AUTOSAR XML (schema 00044)
package /ComponentTypes
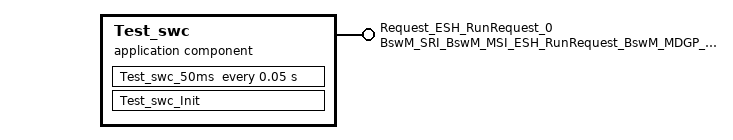
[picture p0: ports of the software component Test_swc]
  application sw component type Test_swc
    provide port Request_ESH_RunRequest_0: nonqueued-sender-com-spec=requestedMode, provided-interface=BswM_SRI_BswM_MSI_ESH_RunRequest_BswM_MDGP_ESH_RunRequest
    behavior Test_swc_InternalBehavior
      init event Test_swc_InitEvent: start-on-event=Test_swc_Init
      timing event TMT_Test_swc_10ms: start-on-event=Test_swc_50ms, period=0.05
      runnable Test_swc_Init
        data-send-points:
          access SEND_Request_ESH_RunRequest_0_requestedMode: accessed-variable=Request_ESH_RunRequest_0.requestedMode
      runnable Test_swc_50ms
  swc implementation Test_swc_Implementation: behavior=Test_swc_InternalBehavior
